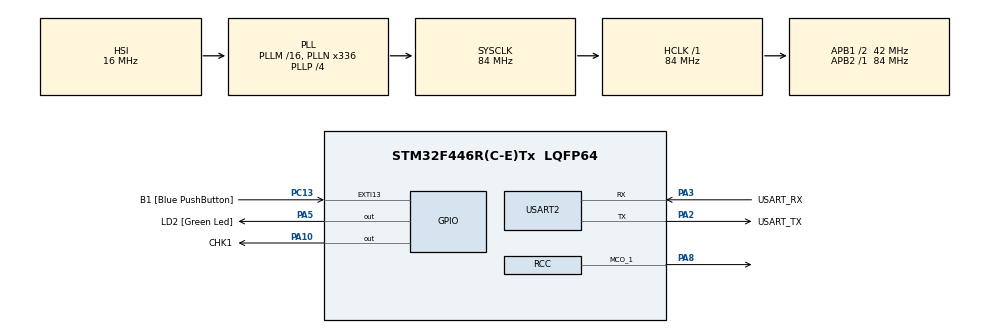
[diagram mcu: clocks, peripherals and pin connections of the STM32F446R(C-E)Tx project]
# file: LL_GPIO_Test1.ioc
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Mcu.Family=STM32F4
Mcu.Name=STM32F446R(C-E)Tx
Mcu.Package=LQFP64
NVIC.PriorityGroup=NVIC_PRIORITYGROUP_0
PA10.GPIO_Label=CHK1
PA10.GPIO_Speed=GPIO_SPEED_FREQ_VERY_HIGH
PA10.Signal=GPIO_Output
PA13.GPIO_Label=TMS
PA13.Mode=Serial_Wire
PA13.Signal=SYS_JTMS-SWDIO
PA14.GPIO_Label=TCK
PA14.Mode=Serial_Wire
PA14.Signal=SYS_JTCK-SWCLK
PA2.GPIO_Label=USART_TX
PA2.Mode=Asynchronous
PA2.Signal=USART2_TX
PA3.GPIO_Label=USART_RX
PA3.Mode=Asynchronous
PA3.Signal=USART2_RX
PA5.GPIO_Label=LD2 [Green Led]
PA5.Signal=GPIO_Output
PA8.Mode=Clock-out-1
PA8.Signal=RCC_MCO_1
PB3.GPIO_Label=SWO
PB3.Signal=SYS_JTDO-SWO
PC13.GPIO_Label=B1 [Blue PushButton]
PC13.GPIO_ModeDefaultEXTI=GPIO_MODE_IT_FALLING
PC13.Signal=GPXTI13
PC14-OSC32_IN.Mode=LSE-External-Oscillator
PC14-OSC32_IN.Signal=RCC_OSC32_IN
PC15-OSC32_OUT.Mode=LSE-External-Oscillator
PC15-OSC32_OUT.Signal=RCC_OSC32_OUT
PH0-OSC_IN.Mode=HSE-External-Oscillator
PH0-OSC_IN.Signal=RCC_OSC_IN
PH1-OSC_OUT.Mode=HSE-External-Oscillator
PH1-OSC_OUT.Signal=RCC_OSC_OUT
ProjectManager.HeapSize=0x200
ProjectManager.StackSize=0x400
ProjectManager.TargetToolchain=SW4STM32
RCC.48MHZClocksFreq_Value=84000000
RCC.AHBFreq_Value=84000000
RCC.APB1CLKDivider=RCC_HCLK_DIV2
RCC.APB1Freq_Value=42000000
RCC.APB1TimFreq_Value=84000000
RCC.APB2Freq_Value=84000000
RCC.APB2TimFreq_Value=84000000
RCC.CortexFreq_Value=84000000
RCC.FLatency-AdvancedSettings=FLASH_LATENCY_2
RCC.HCLKFreq_Value=84000000
RCC.HSE_VALUE=8000000
RCC.HSI_VALUE=16000000
RCC.PLLN=336
RCC.PLLP=RCC_PLLP_DIV4
RCC.SYSCLKFreq_VALUE=84000000
RCC.SYSCLKSource=RCC_SYSCLKSOURCE_PLLCLK
RCC.USBFreq_Value=168000000
RCC.VCOOutputFreq_Value=336000000
USART2.VirtualMode=VM_ASYNC
board=NUCLEO-F446RE

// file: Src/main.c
/* USER CODE BEGIN Header */
/**
  ******************************************************************************
  * @file           : main.c
  * @brief          : Main program body
  ******************************************************************************
  * @attention
  *
  * <h2><center>&copy; Copyright (c) 2019 STMicroelectronics.
  * All rights reserved.</center></h2>
  *
  * This software component is licensed by ST under BSD 3-Clause license,
  * the "License"; You may not use this file except in compliance with the
  * License. You may obtain a copy of the License at:
  *                        opensource.org/licenses/BSD-3-Clause
  *
  ******************************************************************************
  */
/* USER CODE END Header */

#include "main.h"

UART_HandleTypeDef huart2;

void SystemClock_Config(void);
static void MX_GPIO_Init(void);
static void MX_USART2_UART_Init(void);

int main(void)
{

  /* MCU Configuration--------------------------------------------------------*/

  /* Reset of all peripherals, Initializes the Flash interface and the Systick. */
  HAL_Init();

  /* Configure the system clock */
  SystemClock_Config();

  /* Initialize all configured peripherals */
  MX_GPIO_Init();
  MX_USART2_UART_Init();

  /* Infinite loop */
  while (1)
  {

    /* USER CODE BEGIN 3 */
	LL_GPIO_SetOutputPin(CHK1_GPIO_Port, CHK1_Pin);
	LL_GPIO_ResetOutputPin(CHK1_GPIO_Port, CHK1_Pin);
  }
  /* USER CODE END 3 */
}

void SystemClock_Config(void)
{
  RCC_OscInitTypeDef RCC_OscInitStruct = {0};
  RCC_ClkInitTypeDef RCC_ClkInitStruct = {0};

  /** Configure the main internal regulator output voltage
  */
  __HAL_RCC_PWR_CLK_ENABLE();
  __HAL_PWR_VOLTAGESCALING_CONFIG(PWR_REGULATOR_VOLTAGE_SCALE3);
  /** Initializes the CPU, AHB and APB busses clocks
  */
  RCC_OscInitStruct.OscillatorType = RCC_OSCILLATORTYPE_HSI;
  RCC_OscInitStruct.HSIState = RCC_HSI_ON;
  RCC_OscInitStruct.HSICalibrationValue = RCC_HSICALIBRATION_DEFAULT;
  RCC_OscInitStruct.PLL.PLLState = RCC_PLL_ON;
  RCC_OscInitStruct.PLL.PLLSource = RCC_PLLSOURCE_HSI;
  RCC_OscInitStruct.PLL.PLLM = 16;
  RCC_OscInitStruct.PLL.PLLN = 336;
  RCC_OscInitStruct.PLL.PLLP = RCC_PLLP_DIV4;
  RCC_OscInitStruct.PLL.PLLQ = 2;
  RCC_OscInitStruct.PLL.PLLR = 2;
  if (HAL_RCC_OscConfig(&RCC_OscInitStruct) != HAL_OK)
  {
    Error_Handler();
  }
  /** Initializes the CPU, AHB and APB busses clocks
  */
  RCC_ClkInitStruct.ClockType = RCC_CLOCKTYPE_HCLK|RCC_CLOCKTYPE_SYSCLK
                              |RCC_CLOCKTYPE_PCLK1|RCC_CLOCKTYPE_PCLK2;
  RCC_ClkInitStruct.SYSCLKSource = RCC_SYSCLKSOURCE_PLLCLK;
  RCC_ClkInitStruct.AHBCLKDivider = RCC_SYSCLK_DIV1;
  RCC_ClkInitStruct.APB1CLKDivider = RCC_HCLK_DIV2;
  RCC_ClkInitStruct.APB2CLKDivider = RCC_HCLK_DIV1;

  if (HAL_RCC_ClockConfig(&RCC_ClkInitStruct, FLASH_LATENCY_2) != HAL_OK)
  {
    Error_Handler();
  }
  HAL_RCC_MCOConfig(RCC_MCO1, RCC_MCO1SOURCE_HSI, RCC_MCODIV_1);
}

static void MX_USART2_UART_Init(void)
{

  huart2.Instance = USART2;
  huart2.Init.BaudRate = 115200;
  huart2.Init.WordLength = UART_WORDLENGTH_8B;
  huart2.Init.StopBits = UART_STOPBITS_1;
  huart2.Init.Parity = UART_PARITY_NONE;
  huart2.Init.Mode = UART_MODE_TX_RX;
  huart2.Init.HwFlowCtl = UART_HWCONTROL_NONE;
  huart2.Init.OverSampling = UART_OVERSAMPLING_16;
  if (HAL_UART_Init(&huart2) != HAL_OK)
  {
    Error_Handler();
  }

}

static void MX_GPIO_Init(void)
{
  LL_EXTI_InitTypeDef EXTI_InitStruct = {0};
  LL_GPIO_InitTypeDef GPIO_InitStruct = {0};

  /* GPIO Ports Clock Enable */
  LL_AHB1_GRP1_EnableClock(LL_AHB1_GRP1_PERIPH_GPIOC);
  LL_AHB1_GRP1_EnableClock(LL_AHB1_GRP1_PERIPH_GPIOH);
  LL_AHB1_GRP1_EnableClock(LL_AHB1_GRP1_PERIPH_GPIOA);
  LL_AHB1_GRP1_EnableClock(LL_AHB1_GRP1_PERIPH_GPIOB);

  /**/
  LL_GPIO_ResetOutputPin(GPIOA, LD2_Pin|CHK1_Pin);

  /**/
  LL_SYSCFG_SetEXTISource(LL_SYSCFG_EXTI_PORTC, LL_SYSCFG_EXTI_LINE13);

  /**/
  EXTI_InitStruct.Line_0_31 = LL_EXTI_LINE_13;
  EXTI_InitStruct.LineCommand = ENABLE;
  EXTI_InitStruct.Mode = LL_EXTI_MODE_IT;
  EXTI_InitStruct.Trigger = LL_EXTI_TRIGGER_FALLING;
  LL_EXTI_Init(&EXTI_InitStruct);

  /**/
  LL_GPIO_SetPinPull(B1_GPIO_Port, B1_Pin, LL_GPIO_PULL_NO);

  /**/
  LL_GPIO_SetPinMode(B1_GPIO_Port, B1_Pin, LL_GPIO_MODE_INPUT);

  /**/
  GPIO_InitStruct.Pin = LD2_Pin;
  GPIO_InitStruct.Mode = LL_GPIO_MODE_OUTPUT;
  GPIO_InitStruct.Speed = LL_GPIO_SPEED_FREQ_LOW;
  GPIO_InitStruct.OutputType = LL_GPIO_OUTPUT_PUSHPULL;
  GPIO_InitStruct.Pull = LL_GPIO_PULL_NO;
  LL_GPIO_Init(LD2_GPIO_Port, &GPIO_InitStruct);

  /**/
  GPIO_InitStruct.Pin = LL_GPIO_PIN_8;
  GPIO_InitStruct.Mode = LL_GPIO_MODE_ALTERNATE;
  GPIO_InitStruct.Speed = LL_GPIO_SPEED_FREQ_LOW;
  GPIO_InitStruct.OutputType = LL_GPIO_OUTPUT_PUSHPULL;
  GPIO_InitStruct.Pull = LL_GPIO_PULL_NO;
  GPIO_InitStruct.Alternate = LL_GPIO_AF_0;
  LL_GPIO_Init(GPIOA, &GPIO_InitStruct);

  /**/
  GPIO_InitStruct.Pin = CHK1_Pin;
  GPIO_InitStruct.Mode = LL_GPIO_MODE_OUTPUT;
  GPIO_InitStruct.Speed = LL_GPIO_SPEED_FREQ_VERY_HIGH;
  GPIO_InitStruct.OutputType = LL_GPIO_OUTPUT_PUSHPULL;
  GPIO_InitStruct.Pull = LL_GPIO_PULL_NO;
  LL_GPIO_Init(CHK1_GPIO_Port, &GPIO_InitStruct);

}

void Error_Handler(void)
{
}

/************************ (C) COPYRIGHT STMicroelectronics *****END OF FILE****/
